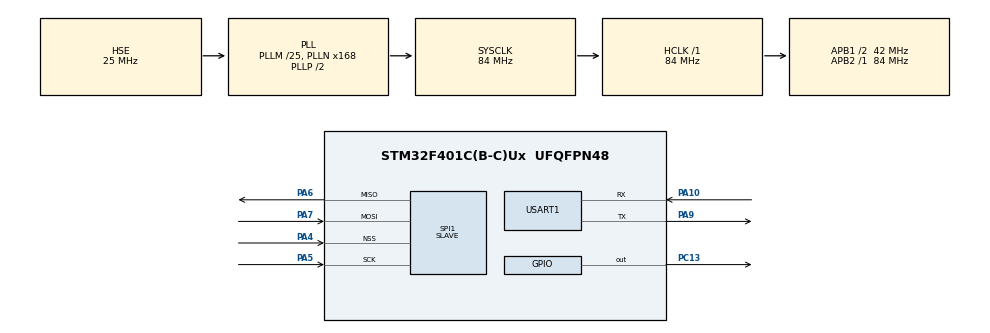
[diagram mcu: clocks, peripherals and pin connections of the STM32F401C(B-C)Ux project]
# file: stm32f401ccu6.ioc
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Dma.Request0=SPI1_RX
Dma.SPI1_RX.0.Direction=DMA_PERIPH_TO_MEMORY
Dma.SPI1_RX.0.FIFOMode=DMA_FIFOMODE_DISABLE
Dma.SPI1_RX.0.Instance=DMA2_Stream0
Dma.SPI1_RX.0.MemDataAlignment=DMA_MDATAALIGN_BYTE
Dma.SPI1_RX.0.MemInc=DMA_MINC_ENABLE
Dma.SPI1_RX.0.Mode=DMA_CIRCULAR
Dma.SPI1_RX.0.PeriphDataAlignment=DMA_PDATAALIGN_BYTE
Dma.SPI1_RX.0.PeriphInc=DMA_PINC_DISABLE
Dma.SPI1_RX.0.Priority=DMA_PRIORITY_LOW
Mcu.Family=STM32F4
Mcu.Name=STM32F401C(B-C)Ux
Mcu.Package=UFQFPN48
NVIC.DMA2_Stream0_IRQn=true\:0\:0\:false\:false\:true\:false\:true\:true
NVIC.PriorityGroup=NVIC_PRIORITYGROUP_4
NVIC.SPI1_IRQn=true\:0\:0\:false\:false\:true\:true\:true\:true
NVIC.USART1_IRQn=true\:0\:0\:false\:false\:true\:true\:true\:true
PA10.Mode=Asynchronous
PA10.Signal=USART1_RX
PA13.Mode=Serial_Wire
PA13.Signal=SYS_JTMS-SWDIO
PA14.Mode=Serial_Wire
PA14.Signal=SYS_JTCK-SWCLK
PA4.Mode=NSS_Signal_Hard_Input
PA4.Signal=SPI1_NSS
PA5.Mode=Full_Duplex_Slave
PA5.Signal=SPI1_SCK
PA6.Mode=Full_Duplex_Slave
PA6.Signal=SPI1_MISO
PA7.Mode=Full_Duplex_Slave
PA7.Signal=SPI1_MOSI
PA9.Mode=Asynchronous
PA9.Signal=USART1_TX
PC13-ANTI_TAMP.Signal=GPIO_Output
PH0\ -\ OSC_IN.Mode=HSE-External-Oscillator
PH0\ -\ OSC_IN.Signal=RCC_OSC_IN
PH1\ -\ OSC_OUT.Mode=HSE-External-Oscillator
PH1\ -\ OSC_OUT.Signal=RCC_OSC_OUT
ProjectManager.HeapSize=0x200
ProjectManager.StackSize=0x400
ProjectManager.TargetToolchain=STM32CubeIDE
RCC.48MHZClocksFreq_Value=42000000
RCC.AHBFreq_Value=84000000
RCC.APB1CLKDivider=RCC_HCLK_DIV2
RCC.APB1Freq_Value=42000000
RCC.APB1TimFreq_Value=84000000
RCC.APB2Freq_Value=84000000
RCC.APB2TimFreq_Value=84000000
RCC.CortexFreq_Value=84000000
RCC.HCLKFreq_Value=84000000
RCC.HSE_VALUE=25000000
RCC.HSI_VALUE=16000000
RCC.LSE_VALUE=32768
RCC.PLLM=25
RCC.PLLN=168
RCC.PLLSourceVirtual=RCC_PLLSOURCE_HSE
RCC.SYSCLKFreq_VALUE=84000000
RCC.SYSCLKSource=RCC_SYSCLKSOURCE_PLLCLK
RCC.VCOOutputFreq_Value=168000000
SPI1.Direction=SPI_DIRECTION_2LINES
SPI1.Mode=SPI_MODE_SLAVE
SPI1.VirtualNSS=VM_NSSHARD
SPI1.VirtualType=VM_SLAVE
USART1.VirtualMode=VM_ASYNC
board=custom

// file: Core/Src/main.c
/* USER CODE BEGIN Header */
/**
  ******************************************************************************
  * @file           : main.c
  * @brief          : Main program body
  ******************************************************************************
  * @attention
  *
  * Copyright (c) 2026 STMicroelectronics.
  * All rights reserved.
  *
  * This software is licensed under terms that can be found in the LICENSE file
  * in the root directory of this software component.
  * If no LICENSE file comes with this software, it is provided AS-IS.
  *
  ******************************************************************************
  */
/* USER CODE END Header */
#include "main.h"
#include "dma.h"
#include "spi.h"
#include "usart.h"
#include "gpio.h"
#include "uart_app.h"
#include <stdio.h>

void SystemClock_Config(void);

int main(void)
{

  /* MCU Configuration--------------------------------------------------------*/

  /* Reset of all peripherals, Initializes the Flash interface and the Systick. */
  HAL_Init();

  /* Configure the system clock */
  SystemClock_Config();

  /* Initialize all configured peripherals */
  MX_GPIO_Init();
  MX_DMA_Init();
  MX_SPI1_Init();
  MX_USART1_UART_Init();
  /* USER CODE BEGIN 2 */
//  uint8_t startup_msg[] = "UART test: device started\r\n";
//  HAL_UART_Transmit(&huart1, startup_msg, sizeof(startup_msg) - 1, HAL_MAX_DELAY);
  UART_App_Init();
  uint32_t last_stat_tick = 0;
  /* USER CODE END 2 */

  /* Infinite loop */
  /* USER CODE BEGIN WHILE */
//  while (1)
//  {
//    /* USER CODE END WHILE */
//	uint8_t byte;
//	while(UART_App_ReadByte(&byte)){
//		HAL_UART_Transmit(&huart1, &byte, 1, HAL_MAX_DELAY);
//	}
//
//	HAL_GPIO_TogglePin(GPIOC, GPIO_PIN_13);
//    HAL_Delay(500);
////
////    uint8_t tick_msg[] = "tick\r\n";
////    HAL_UART_Transmit(&huart1, tick_msg, sizeof(tick_msg) - 1, HAL_MAX_DELAY);
//
//    /* USER CODE BEGIN 3 */
//  }
//  while (1)
//  {
//      /* USER CODE END WHILE */
//      uint8_t byte;
//      while(UART_App_ReadByte(&byte)){
//          HAL_UART_Transmit(&huart1, &byte, 1, HAL_MAX_DELAY);
//          unsigned long tlp = (unsigned long)UART_App_GetTimeFromLastByte();
//          if (byte == '\r')
//          {
//              char dbg_msg[64];
//              unsigned long gbc = (unsigned long)UART_App_GetByteCount();
//              unsigned long goc = (unsigned long)UART_App_GetOverflowCount();
//              unsigned long spd = (unsigned long)UART_App_GetSpeed();
//              int dbg_len = sprintf(dbg_msg, "\r\n[rx_byte_count=%lu, overflow=%lu, speed=%lu B/s, pause=%lu s]\r\n",
//                                     gbc,
//                                     goc,
//									 spd,
//									 tlp);
//              HAL_UART_Transmit(&huart1, (uint8_t *)dbg_msg, dbg_len, HAL_MAX_DELAY);
////              uint32_t maxi = 4294967295;
////              char dbg_msg2[64];
////              int rnd = sprintf(dbg_msg2, "\r\nMax of this type: %lu\r\n", maxi);
////              HAL_UART_Transmit(&huart1, (uint8_t *)dbg_msg2, rnd, HAL_MAX_DELAY);
//          }
//
//      }
//
////      HAL_GPIO_TogglePin(GPIOC, GPIO_PIN_13);
////      HAL_Delay(5000);
//
//      /* USER CODE BEGIN 3 */
//  }
  while (1)
  {
      /* USER CODE END WHILE */
      uint8_t byte;
      while (UART_App_ReadByte(&byte))
      {
          HAL_UART_Transmit(&huart1, &byte, 1, HAL_MAX_DELAY);
      }

      /* раз в секунду отправляем статистику сами */
      if (HAL_GetTick() - last_stat_tick >= 1000)
      {
          last_stat_tick = HAL_GetTick();

          char stat[64];
          unsigned long gbc = (unsigned long)UART_App_GetByteCount();
          unsigned long goc = (unsigned long)UART_App_GetOverflowCount();
          unsigned long spd = (unsigned long)UART_App_GetSpeed();
          // unsigned long tlp = (unsigned long)UART_App_GetTimeFromLastByte();
          unsigned long buf = (unsigned long)UART_App_GetBufferedCount();
          int len = sprintf(stat,
              "[rx_byte_count=%lu,overflow=%lu,speed=%lu,buffered=%lu]\r\n",
              gbc, goc, spd, buf);
          HAL_UART_Transmit(&huart1, (uint8_t *)stat, len, HAL_MAX_DELAY);
      }

  }
}

void SystemClock_Config(void)
{
  RCC_OscInitTypeDef RCC_OscInitStruct = {0};
  RCC_ClkInitTypeDef RCC_ClkInitStruct = {0};

  /** Configure the main internal regulator output voltage
  */
  __HAL_RCC_PWR_CLK_ENABLE();
  __HAL_PWR_VOLTAGESCALING_CONFIG(PWR_REGULATOR_VOLTAGE_SCALE2);

  /** Initializes the RCC Oscillators according to the specified parameters
  * in the RCC_OscInitTypeDef structure.
  */
  RCC_OscInitStruct.OscillatorType = RCC_OSCILLATORTYPE_HSE;
  RCC_OscInitStruct.HSEState = RCC_HSE_ON;
  RCC_OscInitStruct.PLL.PLLState = RCC_PLL_ON;
  RCC_OscInitStruct.PLL.PLLSource = RCC_PLLSOURCE_HSE;
  RCC_OscInitStruct.PLL.PLLM = 25;
  RCC_OscInitStruct.PLL.PLLN = 168;
  RCC_OscInitStruct.PLL.PLLP = RCC_PLLP_DIV2;
  RCC_OscInitStruct.PLL.PLLQ = 4;
  if (HAL_RCC_OscConfig(&RCC_OscInitStruct) != HAL_OK)
  {
    Error_Handler();
  }

  /** Initializes the CPU, AHB and APB buses clocks
  */
  RCC_ClkInitStruct.ClockType = RCC_CLOCKTYPE_HCLK|RCC_CLOCKTYPE_SYSCLK
                              |RCC_CLOCKTYPE_PCLK1|RCC_CLOCKTYPE_PCLK2;
  RCC_ClkInitStruct.SYSCLKSource = RCC_SYSCLKSOURCE_PLLCLK;
  RCC_ClkInitStruct.AHBCLKDivider = RCC_SYSCLK_DIV1;
  RCC_ClkInitStruct.APB1CLKDivider = RCC_HCLK_DIV2;
  RCC_ClkInitStruct.APB2CLKDivider = RCC_HCLK_DIV1;

  if (HAL_RCC_ClockConfig(&RCC_ClkInitStruct, FLASH_LATENCY_2) != HAL_OK)
  {
    Error_Handler();
  }
}

void Error_Handler(void)
{
  __disable_irq();
  while (1)
  {
  }
}
